# STM32U3B5 register map
File version: 1.0
CPU: CM33 r0p1, little endian, MPU, FPU, 4 interrupt priority bits
Registers are 32-bit, read-write, reset 0x0 unless marked. A register's access mark holds for its fields unless they carry their own. Offsets are from the block's base; [hi:lo] are bit positions; {n}, {i} and the like mark numbered series.

## DBGMCU — DBGMCU address block description
Base 0xE0044000
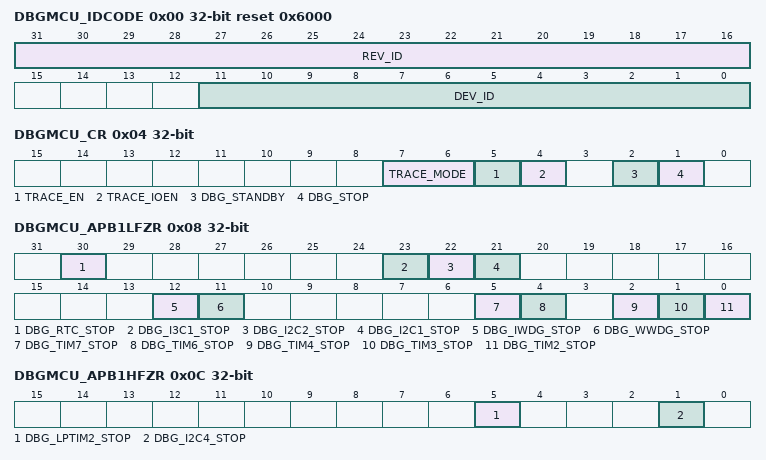
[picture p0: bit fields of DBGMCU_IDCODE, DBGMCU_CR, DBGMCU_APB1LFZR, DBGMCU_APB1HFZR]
0x00 DBGMCU_IDCODE ro reset 0x6000 (reset mask 0xF000) — DBGMCU identity code register
  [31:16] REV_ID — Revision
    0x1000=Revision A; 0x1001=Revision Z
  [11:0] DEV_ID — Device identification
    0x454=STM32U375/385; 0x42A=STM32U3B5/3C5
0x04 DBGMCU_CR — DBGMCU configuration register
  [7:6] TRACE_MODE — Trace pin assignment
    0=Trace pins assigned for asynchronous mode (TRACESWO); 1=Trace pins assigned for synchronous mode with a port width of 1 (TRACECK, TRACED0); 2=Trace pins assigned for synchronous mode with a port width of 2 (TRACECK, TRACED0-1); 3=Trace pins assigned for synchronous mode with a port width of 4 (TRACECK, TRACED0-3)
  [5] TRACE_EN — Trace port and clock enable.
    0=Disabled; 1=Enabled
  [4] TRACE_IOEN — Trace pin enable
    0=Disabled - trace pins not assigned; 1=Enabled - trace pins assigned according to the value of TRACE_MODE bit field
  [2] DBG_STANDBY — Allows debug in Standby mode
    0=Normal operation; 1=Automatic clock stop/power-down disabled
  [1] DBG_STOP — Allows debug in Stop mode
    0=Normal operation; 1=Automatic clock stop disabled
0x08 DBGMCU_APB1LFZR — DBGMCU APB1L peripheral freeze register
  [all] fields
    0=Normal operation; 1=Stop in debug
  [30] DBG_RTC_STOP — RTC stop in debug
  [23] DBG_I3C1_STOP — I3C1 timeout stop in debug
  [22] DBG_I2C2_STOP — I2C2 SMBUS timeout stop in debug
  [21] DBG_I2C1_STOP — I2C1 SMBUS timeout stop in debug
  [12] DBG_IWDG_STOP — IWDG stop in debug
  [11] DBG_WWDG_STOP — WWDG stop in debug
  [5] DBG_TIM7_STOP — TIMy stop in debug
  [4] DBG_TIM6_STOP — TIMy stop in debug
  [2] DBG_TIM4_STOP — TIMy stop in debug
  [1] DBG_TIM3_STOP — TIMy stop in debug
  [0] DBG_TIM2_STOP — TIMy stop in debug
0x0C DBGMCU_APB1HFZR — DBGMCU APB1H peripheral freeze register
  [5] DBG_LPTIM2_STOP — LPTIM2 stop in debug
    0=Normal operation; 1=Stop in debug
  [1] DBG_I2C4_STOP — I2C4 SMBUS timeout stop in debug
    0=Normal operation; 1=Stop in debug
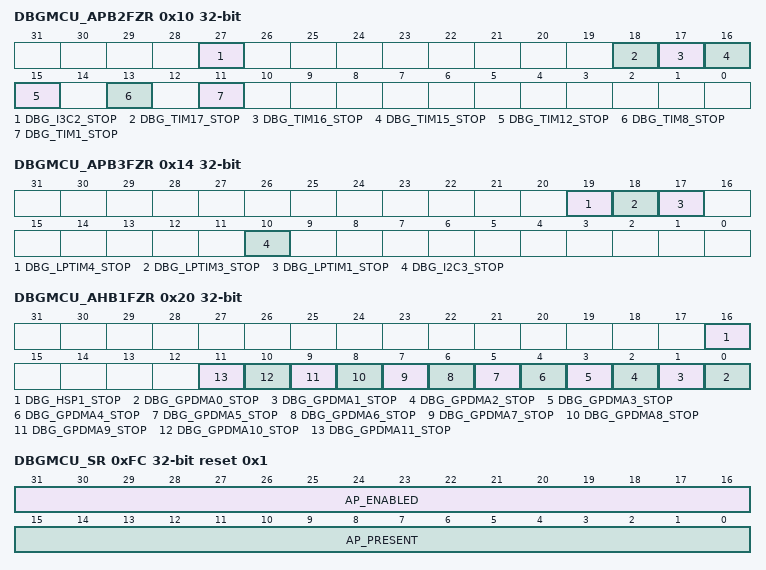
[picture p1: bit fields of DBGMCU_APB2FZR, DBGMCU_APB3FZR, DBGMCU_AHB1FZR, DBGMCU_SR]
0x10 DBGMCU_APB2FZR — DBGMCU APB2 peripheral freeze register
  [27] DBG_I3C2_STOP — I3C2 timeout stop in debug
    0=Normal operation; 1=Normal in debug
  [18] DBG_TIM17_STOP — TIMy stop in debug
    0=Normal operation; 1=Stop in debug
  [17] DBG_TIM16_STOP — TIMy stop in debug
    0=Normal operation; 1=Stop in debug
  [16] DBG_TIM15_STOP — TIMy stop in debug
    0=Normal operation; 1=Stop in debug
  [15] DBG_TIM12_STOP — TIM12 stop in debug
    0=Normal operation; 1=Stop in debug
  [13] DBG_TIM8_STOP — TIM8 stop in debug
    0=Normal operation; 1=Stop in debug
  [11] DBG_TIM1_STOP — TIM1 stop in debug
    0=Normal operation; 1=Stop in debug
0x14 DBGMCU_APB3FZR — DBGMCU APB3 peripheral freeze register
  [all] fields
    0=Normal operation; 1=Stop in debug
  [19] DBG_LPTIM4_STOP — LPTIM4 stop in debug
  [18] DBG_LPTIM3_STOP — LPTIM3 stop in debug
  [17] DBG_LPTIM1_STOP — LPTIM1 stop in debug
  [10] DBG_I2C3_STOP — I2C3 stop in debug
0x20 DBGMCU_AHB1FZR — DBGMCU AHB1 peripheral freeze register
  [all] fields
    0=normal operation; 1=stop in debug
  [16] DBG_HSP1_STOP — HSP1 stop in debug
  [n] DBG_GPDMA{n}_STOP (n=0..11) — GPDMA channel y stop in debug
0xFC DBGMCU_SR ro reset 0x1 (reset mask 0xFFFF) — DBGMCU status register
  [31:16] AP_ENABLED — Bit n identifies whether access port AP n is open (can be accessed via the debug port) or locked (debug access to the AP is blocked)
  [15:0] AP_PRESENT — Bit n identifies whether access port AP n is present in device
0x100 DBGMCU_DBG_AUTH_HOST wo reset not defined — DBGMCU debug host authentication register
  [31:0] AUTH_KEY — Device authentication key
0x104 DBGMCU_DBG_AUTH_DEVICE ro reset not defined — DBGMCU debug device authentication register
  [31:0] AUTH_ID — Device specific authentication ID
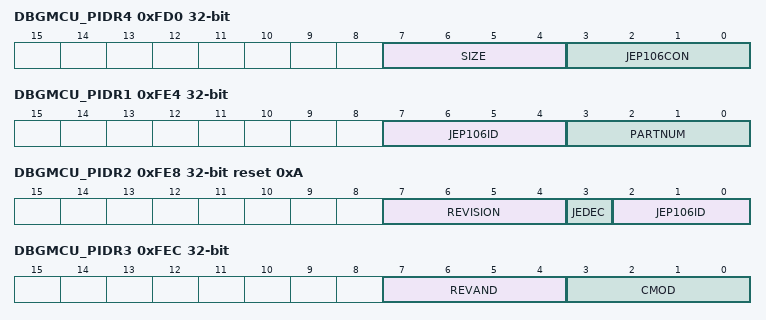
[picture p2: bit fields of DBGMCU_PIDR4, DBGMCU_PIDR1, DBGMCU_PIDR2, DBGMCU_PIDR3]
0xFD0 DBGMCU_PIDR4 ro — DBGMCU CoreSight peripheral identity register 4
  [7:4] SIZE — Register file size
    0=The register file occupies a single 4-Kbyte region
  [3:0] JEP106CON — JEP106 continuation code
    0=STMicroelectronics JEDEC code
0xFE0 DBGMCU_PIDR0 ro — DBGMCU CoreSight peripheral identity register 0
  [7:0] PARTNUM — Part number bits [7:0]
    0=DBGMCU part number
0xFE4 DBGMCU_PIDR1 ro — DBGMCU CoreSight peripheral identity register 1
  [7:4] JEP106ID — JEP106 identity code bits [3:0]
    0=STMicroelectronics JEDEC code
  [3:0] PARTNUM — Part number bits [11:8]
    0=DBGMCU part number
0xFE8 DBGMCU_PIDR2 ro reset 0xA — DBGMCU CoreSight peripheral identity register 2
  [7:4] REVISION — Component revision number
    0=r0p0
  [3] JEDEC — JEDEC assigned value
    1=designer identification specified by JEDEC
  [2:0] JEP106ID — JEP106 identity code bits [6:4]
    2=STMicroelectronics JEDEC code
0xFEC DBGMCU_PIDR3 ro — DBGMCU CoreSight peripheral identity register 3
  [7:4] REVAND — Metal fix version
    0=No metal fix
  [3:0] CMOD — Customer modified
    0=No customer modifications
0xFF0 DBGMCU_CIDR0 ro reset 0xD — DBGMCU CoreSight component identity register 0
  [7:0] PREAMBLE — Component identification bits [7:0]
    13=Common identification value
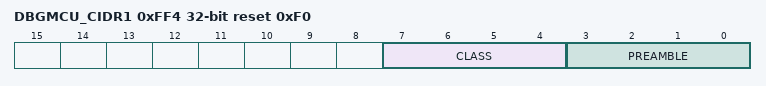
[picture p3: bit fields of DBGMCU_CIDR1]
0xFF4 DBGMCU_CIDR1 ro reset 0xF0 — DBGMCU CoreSight component identity register 1
  [7:4] CLASS — Component identification bits [15:12] - component class
    15=Non-CoreSight component
  [3:0] PREAMBLE — Component identification bits [11:8]
    0=Common identification value
0xFF8 DBGMCU_CIDR2 ro reset 0x5 — DBGMCU CoreSight component identity register 2
  [7:0] PREAMBLE — Component identification bits [23:16]
    5=Common identification value
0xFFC DBGMCU_CIDR3 ro reset 0xB1 — DBGMCU CoreSight component identity register 3
  [7:0] PREAMBLE — Component identification bits [31:24]
    177=Common identification value
